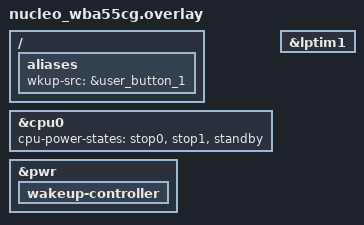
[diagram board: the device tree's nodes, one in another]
/*
 * Copyright (c) 2025 STMicroelectronics
 *
 * SPDX-License-Identifier: Apache-2.0
 */

/ {
	aliases {
		wkup-src = &user_button_1;
	};
};

&cpu0 {
	cpu-power-states = <&stop0 &stop1 &standby>;
};

&lptim1 {
	status = "okay";
};

&pwr {
	wakeup-controller {
		status = "okay";
	};
};
